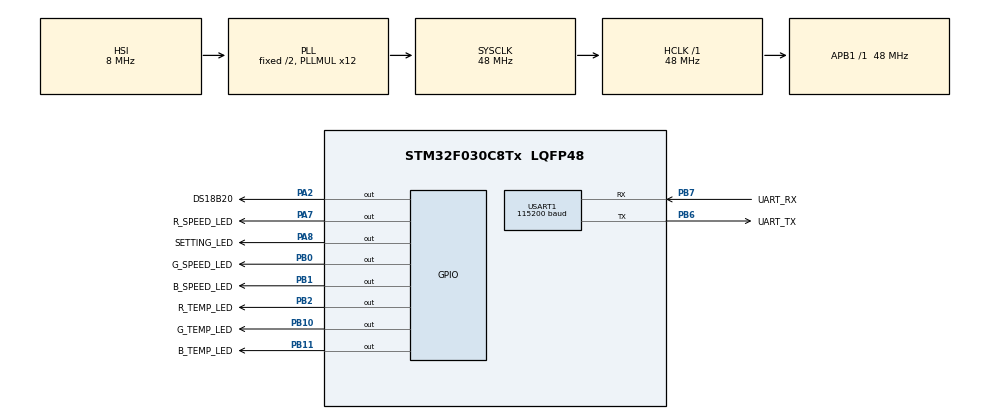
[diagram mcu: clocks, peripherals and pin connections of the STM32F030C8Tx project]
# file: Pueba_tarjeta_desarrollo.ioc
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Mcu.Family=STM32F0
Mcu.Name=STM32F030C8Tx
Mcu.Package=LQFP48
NVIC.USART1_IRQn=true\:0\:0\:false\:false\:true\:true\:true\:true
PA2.GPIO_Label=DS18B20
PA2.Signal=GPIO_Output
PA7.GPIO_Label=R_SPEED_LED
PA7.PinState=GPIO_PIN_RESET
PA7.Signal=GPIO_Output
PA8.GPIO_Label=SETTING_LED
PA8.PinState=GPIO_PIN_SET
PA8.Signal=GPIO_Output
PB0.GPIO_Label=G_SPEED_LED
PB0.PinState=GPIO_PIN_RESET
PB0.Signal=GPIO_Output
PB1.GPIO_Label=B_SPEED_LED
PB1.PinState=GPIO_PIN_RESET
PB1.Signal=GPIO_Output
PB10.GPIO_Label=G_TEMP_LED
PB10.PinState=GPIO_PIN_RESET
PB10.Signal=GPIO_Output
PB11.GPIO_Label=B_TEMP_LED
PB11.PinState=GPIO_PIN_RESET
PB11.Signal=GPIO_Output
PB2.GPIO_Label=R_TEMP_LED
PB2.PinState=GPIO_PIN_RESET
PB2.Signal=GPIO_Output
PB6.GPIO_Label=UART_TX
PB6.Mode=Asynchronous
PB6.Signal=USART1_TX
PB7.GPIO_Label=UART_RX
PB7.Mode=Asynchronous
PB7.Signal=USART1_RX
ProjectManager.HeapSize=0x200
ProjectManager.StackSize=0x400
ProjectManager.TargetToolchain=STM32CubeIDE
RCC.AHBFreq_Value=48000000
RCC.APB1Freq_Value=48000000
RCC.APB1TimFreq_Value=48000000
RCC.HCLKFreq_Value=48000000
RCC.PLLMUL=RCC_PLL_MUL12
RCC.SYSCLKFreq_VALUE=48000000
RCC.SYSCLKSource=RCC_SYSCLKSOURCE_PLLCLK
TIM3.Period=0xffff-1
TIM3.Prescaler=48-1
USART1.BaudRate=115200
USART1.VirtualMode-Asynchronous=VM_ASYNC
VP_TIM3_VS_ClockSourceINT.Mode=Internal
board=custom

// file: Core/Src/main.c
/* USER CODE BEGIN Header */
/**
  ******************************************************************************
  * @file           : main.c
  * @brief          : Main program body
  ******************************************************************************
  * @attention
  *
  * Copyright (c) 2024 STMicroelectronics.
  * All rights reserved.
  *
  * This software is licensed under terms that can be found in the LICENSE file
  * in the root directory of this software component.
  * If no LICENSE file comes with this software, it is provided AS-IS.
  *
  ******************************************************************************
  */
/* USER CODE END Header */
#include "main.h"

TIM_HandleTypeDef htim3;

UART_HandleTypeDef huart1;

void SystemClock_Config(void);
static void MX_GPIO_Init(void);
static void MX_USART1_UART_Init(void);
static void MX_TIM3_Init(void);

/* USER CODE BEGIN 0 */
uint8_t transmit_text[128];
uint8_t size_to_send;
/* USER CODE END 0 */

int main(void)
{

  /* MCU Configuration--------------------------------------------------------*/

  /* Reset of all peripherals, Initializes the Flash interface and the Systick. */
  HAL_Init();

  /* Configure the system clock */
  SystemClock_Config();

  /* Initialize all configured peripherals */
  MX_GPIO_Init();
  MX_USART1_UART_Init();
  MX_TIM3_Init();
  /* USER CODE BEGIN 2 */
  HAL_TIM_Base_Start_IT(&htim3);
  /* USER CODE END 2 */

  /* Infinite loop */
  /* USER CODE BEGIN WHILE */
  while (1)
  {

	  float temperature = Get_temperature();
	  size_to_send = sprintf((char *)&transmit_text, "Temperature = %0.2f °C \r\n\n", temperature);
	  HAL_UART_Transmit(&huart1, (const uint8_t *)&transmit_text, size_to_send, 500);

	  HAL_Delay(1000);

    /* USER CODE END WHILE */

  }
}

void SystemClock_Config(void)
{
  RCC_OscInitTypeDef RCC_OscInitStruct = {0};
  RCC_ClkInitTypeDef RCC_ClkInitStruct = {0};
  RCC_PeriphCLKInitTypeDef PeriphClkInit = {0};

  /** Initializes the RCC Oscillators according to the specified parameters
  * in the RCC_OscInitTypeDef structure.
  */
  RCC_OscInitStruct.OscillatorType = RCC_OSCILLATORTYPE_HSI;
  RCC_OscInitStruct.HSIState = RCC_HSI_ON;
  RCC_OscInitStruct.HSICalibrationValue = RCC_HSICALIBRATION_DEFAULT;
  RCC_OscInitStruct.PLL.PLLState = RCC_PLL_ON;
  RCC_OscInitStruct.PLL.PLLSource = RCC_PLLSOURCE_HSI;
  RCC_OscInitStruct.PLL.PLLMUL = RCC_PLL_MUL12;
  RCC_OscInitStruct.PLL.PREDIV = RCC_PREDIV_DIV1;
  if (HAL_RCC_OscConfig(&RCC_OscInitStruct) != HAL_OK)
  {
    Error_Handler();
  }

  /** Initializes the CPU, AHB and APB buses clocks
  */
  RCC_ClkInitStruct.ClockType = RCC_CLOCKTYPE_HCLK|RCC_CLOCKTYPE_SYSCLK
                              |RCC_CLOCKTYPE_PCLK1;
  RCC_ClkInitStruct.SYSCLKSource = RCC_SYSCLKSOURCE_PLLCLK;
  RCC_ClkInitStruct.AHBCLKDivider = RCC_SYSCLK_DIV1;
  RCC_ClkInitStruct.APB1CLKDivider = RCC_HCLK_DIV1;

  if (HAL_RCC_ClockConfig(&RCC_ClkInitStruct, FLASH_LATENCY_1) != HAL_OK)
  {
    Error_Handler();
  }
  PeriphClkInit.PeriphClockSelection = RCC_PERIPHCLK_USART1;
  PeriphClkInit.Usart1ClockSelection = RCC_USART1CLKSOURCE_PCLK1;
  if (HAL_RCCEx_PeriphCLKConfig(&PeriphClkInit) != HAL_OK)
  {
    Error_Handler();
  }
}

static void MX_TIM3_Init(void)
{

  TIM_ClockConfigTypeDef sClockSourceConfig = {0};
  TIM_MasterConfigTypeDef sMasterConfig = {0};

  htim3.Instance = TIM3;
  htim3.Init.Prescaler = 48-1;
  htim3.Init.CounterMode = TIM_COUNTERMODE_UP;
  htim3.Init.Period = 0xffff-1;
  htim3.Init.ClockDivision = TIM_CLOCKDIVISION_DIV1;
  htim3.Init.AutoReloadPreload = TIM_AUTORELOAD_PRELOAD_DISABLE;
  if (HAL_TIM_Base_Init(&htim3) != HAL_OK)
  {
    Error_Handler();
  }
  sClockSourceConfig.ClockSource = TIM_CLOCKSOURCE_INTERNAL;
  if (HAL_TIM_ConfigClockSource(&htim3, &sClockSourceConfig) != HAL_OK)
  {
    Error_Handler();
  }
  sMasterConfig.MasterOutputTrigger = TIM_TRGO_RESET;
  sMasterConfig.MasterSlaveMode = TIM_MASTERSLAVEMODE_DISABLE;
  if (HAL_TIMEx_MasterConfigSynchronization(&htim3, &sMasterConfig) != HAL_OK)
  {
    Error_Handler();
  }

}

static void MX_USART1_UART_Init(void)
{

  huart1.Instance = USART1;
  huart1.Init.BaudRate = 115200;
  huart1.Init.WordLength = UART_WORDLENGTH_8B;
  huart1.Init.StopBits = UART_STOPBITS_1;
  huart1.Init.Parity = UART_PARITY_NONE;
  huart1.Init.Mode = UART_MODE_TX_RX;
  huart1.Init.HwFlowCtl = UART_HWCONTROL_NONE;
  huart1.Init.OverSampling = UART_OVERSAMPLING_16;
  huart1.Init.OneBitSampling = UART_ONE_BIT_SAMPLE_DISABLE;
  huart1.AdvancedInit.AdvFeatureInit = UART_ADVFEATURE_NO_INIT;
  if (HAL_UART_Init(&huart1) != HAL_OK)
  {
    Error_Handler();
  }

}

static void MX_GPIO_Init(void)
{
  GPIO_InitTypeDef GPIO_InitStruct = {0};

  /* GPIO Ports Clock Enable */
  __HAL_RCC_GPIOA_CLK_ENABLE();
  __HAL_RCC_GPIOB_CLK_ENABLE();

  /*Configure GPIO pin Output Level */
  HAL_GPIO_WritePin(GPIOA, DS18B20_Pin|R_SPEED_LED_Pin, GPIO_PIN_RESET);

  /*Configure GPIO pin Output Level */
  HAL_GPIO_WritePin(GPIOB, G_SPEED_LED_Pin|B_SPEED_LED_Pin|R_TEMP_LED_Pin|G_TEMP_LED_Pin
                          |B_TEMP_LED_Pin, GPIO_PIN_RESET);

  /*Configure GPIO pin Output Level */
  HAL_GPIO_WritePin(SETTING_LED_GPIO_Port, SETTING_LED_Pin, GPIO_PIN_SET);

  /*Configure GPIO pins : DS18B20_Pin R_SPEED_LED_Pin SETTING_LED_Pin */
  GPIO_InitStruct.Pin = DS18B20_Pin|R_SPEED_LED_Pin|SETTING_LED_Pin;
  GPIO_InitStruct.Mode = GPIO_MODE_OUTPUT_PP;
  GPIO_InitStruct.Pull = GPIO_NOPULL;
  GPIO_InitStruct.Speed = GPIO_SPEED_FREQ_LOW;
  HAL_GPIO_Init(GPIOA, &GPIO_InitStruct);

  /*Configure GPIO pins : G_SPEED_LED_Pin B_SPEED_LED_Pin R_TEMP_LED_Pin G_TEMP_LED_Pin
                           B_TEMP_LED_Pin */
  GPIO_InitStruct.Pin = G_SPEED_LED_Pin|B_SPEED_LED_Pin|R_TEMP_LED_Pin|G_TEMP_LED_Pin
                          |B_TEMP_LED_Pin;
  GPIO_InitStruct.Mode = GPIO_MODE_OUTPUT_PP;
  GPIO_InitStruct.Pull = GPIO_NOPULL;
  GPIO_InitStruct.Speed = GPIO_SPEED_FREQ_LOW;
  HAL_GPIO_Init(GPIOB, &GPIO_InitStruct);

}

void Error_Handler(void)
{
  __disable_irq();
  while (1)
  {
  }
}
